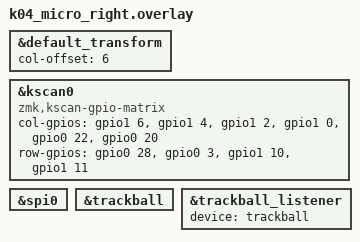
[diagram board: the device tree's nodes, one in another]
#include "k04_micro.dtsi"

&default_transform {
    col-offset = <6>;
};

/*
 * [split.peripheral.matrix] задаёт ТЕ ЖЕ пины, что и central — у K04 Micro
 * половины электрически идентичны. (Для сравнения: у op36 половины разные,
 * там пины левой и правой не совпадают. Здесь совпадение не ошибка, оно
 * прямо прописано в keyboard.toml для обеих секций.)
 */
&kscan0 {
    compatible = "zmk,kscan-gpio-matrix";

    col-gpios
        = <&gpio1 6 GPIO_ACTIVE_HIGH>
        , <&gpio1 4 GPIO_ACTIVE_HIGH>
        , <&gpio1 2 GPIO_ACTIVE_HIGH>
        , <&gpio1 0 GPIO_ACTIVE_HIGH>
        , <&gpio0 22 GPIO_ACTIVE_HIGH>
        , <&gpio0 20 GPIO_ACTIVE_HIGH>
        ;

    row-gpios
        = <&gpio0 28 (GPIO_ACTIVE_HIGH | GPIO_PULL_DOWN)>
        , <&gpio0 3  (GPIO_ACTIVE_HIGH | GPIO_PULL_DOWN)>
        , <&gpio1 10 (GPIO_ACTIVE_HIGH | GPIO_PULL_DOWN)>
        , <&gpio1 11 (GPIO_ACTIVE_HIGH | GPIO_PULL_DOWN)>
        ;
};

/* Правая = central + трекбол: события сенсора идут напрямую в хост,
   без лишнего BLE-хопа через вторую половину. */
&spi0 {
    status = "okay";
};

&trackball {
    status = "okay";
};

&trackball_listener {
    status = "okay";
    device = <&trackball>;
};

/*
 * Правый энкодер НЕ включён: этот отсек занят трекболом — модуль в K:04
 * ставится либо-либо. Узел encoder_R1 объявлен в .dtsi, но остаётся
 * disabled, поэтому в прошивке ничего лишнего не крутится.
 *
 * Если однажды поменяете правый модуль на энкодер — раскомментируйте
 * блок ниже и уберите status="okay" у &spi0 / &trackball / &trackball_listener
 * выше (или соберите отдельный вариант шилда).
 */
/*
&encoder_R1 {
    status = "okay";
};
*/
